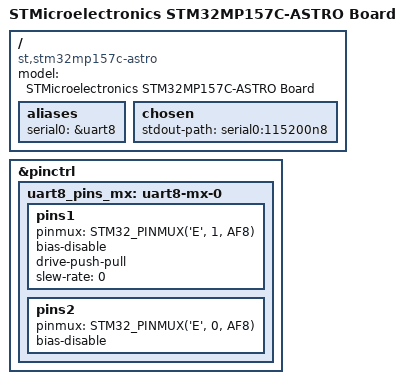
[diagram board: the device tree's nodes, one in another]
// SPDX-License-Identifier: (GPL-2.0+ OR BSD-3-Clause)
/*
 * Copyright (C) STMicroelectronics 2019 - All Rights Reserved
 * Author: Alexandre Torgue <alexandre.torgue@st.com> for STMicroelectronics.
 */
/dts-v1/;

#include "stm32mp157.dtsi"
#include "stm32mp15xc.dtsi"
#include "stm32mp15-pinctrl.dtsi"
#include "stm32mp15xxac-pinctrl.dtsi"
#include "stm32mp157c-astro.dtsi"

/ {
	model = "STMicroelectronics STM32MP157C-ASTRO Board";
	compatible = "st,stm32mp157c-astro", "st,stm32mp157";
	
	aliases {
		serial0 = &uart8;
	};
	
	chosen {
		stdout-path = "serial0:115200n8";
	};
};

&pinctrl {
    uart8_pins_mx: uart8-mx-0 {
        pins1 {
            pinmux = <STM32_PINMUX('E', 1, AF8)>; /* UART8_TX */
            bias-disable;
            drive-push-pull;
            slew-rate = <0>;
        };
        pins2 {
            pinmux = <STM32_PINMUX('E', 0, AF8)>; /* UART8_RX */
            bias-disable;
        };
    };
};

